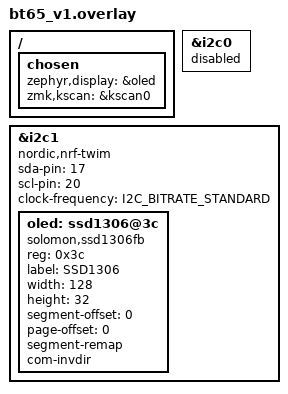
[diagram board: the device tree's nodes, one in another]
/ {
    chosen {
        zephyr,display = &oled;
        zmk,kscan = &kscan0;
    };
};

/* Matikan I2C lain yang tidak dipakai */
&i2c0 {
    status = "disabled";
};

/* Aktifkan I2C1 untuk OLED */
&i2c1 {
    compatible = "nordic,nrf-twim";
    status = "okay";
    sda-pin = <17>;
    scl-pin = <20>;
    clock-frequency = <I2C_BITRATE_STANDARD>; /* 100kHz */

    oled: ssd1306@3c {
        compatible = "solomon,ssd1306fb";
        reg = <0x3c>;
        label = "SSD1306";
        width = <128>;
        height = <32>;
        segment-offset = <0>;
        page-offset = <0>;
        segment-remap;
        com-invdir;
        /* reset-gpios bisa dihapus kalau OLED tidak punya pin reset */
    };
};
